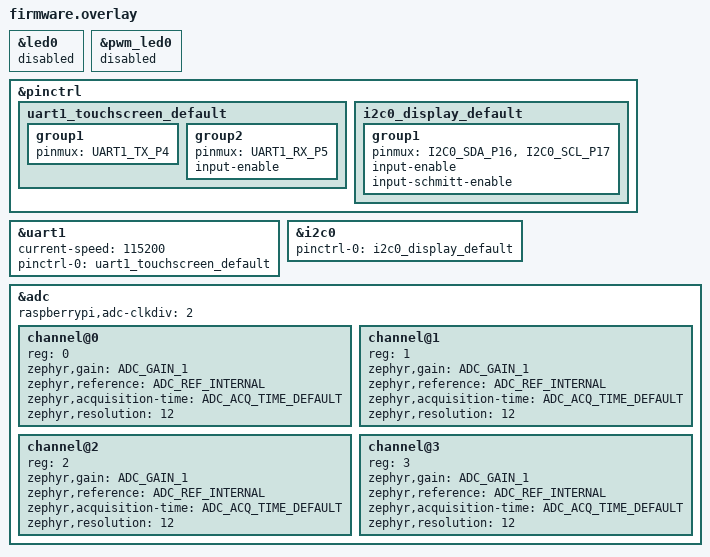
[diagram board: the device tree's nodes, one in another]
#include <zephyr/dt-bindings/pinctrl/rpi-pico-rp2040-pinctrl.h>
&led0 {
    status = "disabled";
};

&pwm_led0 {
    status = "disabled";
};

&pinctrl {
    uart1_touchscreen_default: uart1_touchscreen_default {
        group1 {
            pinmux = <UART1_TX_P4>;
        };

        group2 {
            pinmux = <UART1_RX_P5>;
            input-enable;
        };
    };

    i2c0_display_default: i2c0_display_default {
        group1 {
            pinmux = <I2C0_SDA_P16>, <I2C0_SCL_P17>;
            input-enable;
            input-schmitt-enable;
        };
    };
};

&uart1 {
    current-speed = <115200>;
    status = "okay";
    pinctrl-0 = <&uart1_touchscreen_default>;
    pinctrl-names = "default";
};

&i2c0 {
    status = "okay";
    pinctrl-0 = <&i2c0_display_default>;
    pinctrl-names = "default";
};

&adc {
    raspberrypi,adc-clkdiv = <2>;
    #address-cells = <1>;
    #size-cells = <0>;

    channel@0 {
        reg = <0>;
        zephyr,gain = "ADC_GAIN_1";
        zephyr,reference = "ADC_REF_INTERNAL";
        zephyr,acquisition-time = <ADC_ACQ_TIME_DEFAULT>;
        zephyr,resolution = <12>;
    };

    channel@1 {
        reg = <1>;
        zephyr,gain = "ADC_GAIN_1";
        zephyr,reference = "ADC_REF_INTERNAL";
        zephyr,acquisition-time = <ADC_ACQ_TIME_DEFAULT>;
        zephyr,resolution = <12>;
    };

    channel@2 {
        reg = <2>;
        zephyr,gain = "ADC_GAIN_1";
        zephyr,reference = "ADC_REF_INTERNAL";
        zephyr,acquisition-time = <ADC_ACQ_TIME_DEFAULT>;
        zephyr,resolution = <12>;
    };

    channel@3 {
        reg = <3>;
        zephyr,gain = "ADC_GAIN_1";
        zephyr,reference = "ADC_REF_INTERNAL";
        zephyr,acquisition-time = <ADC_ACQ_TIME_DEFAULT>;
        zephyr,resolution = <12>;
    };
};
